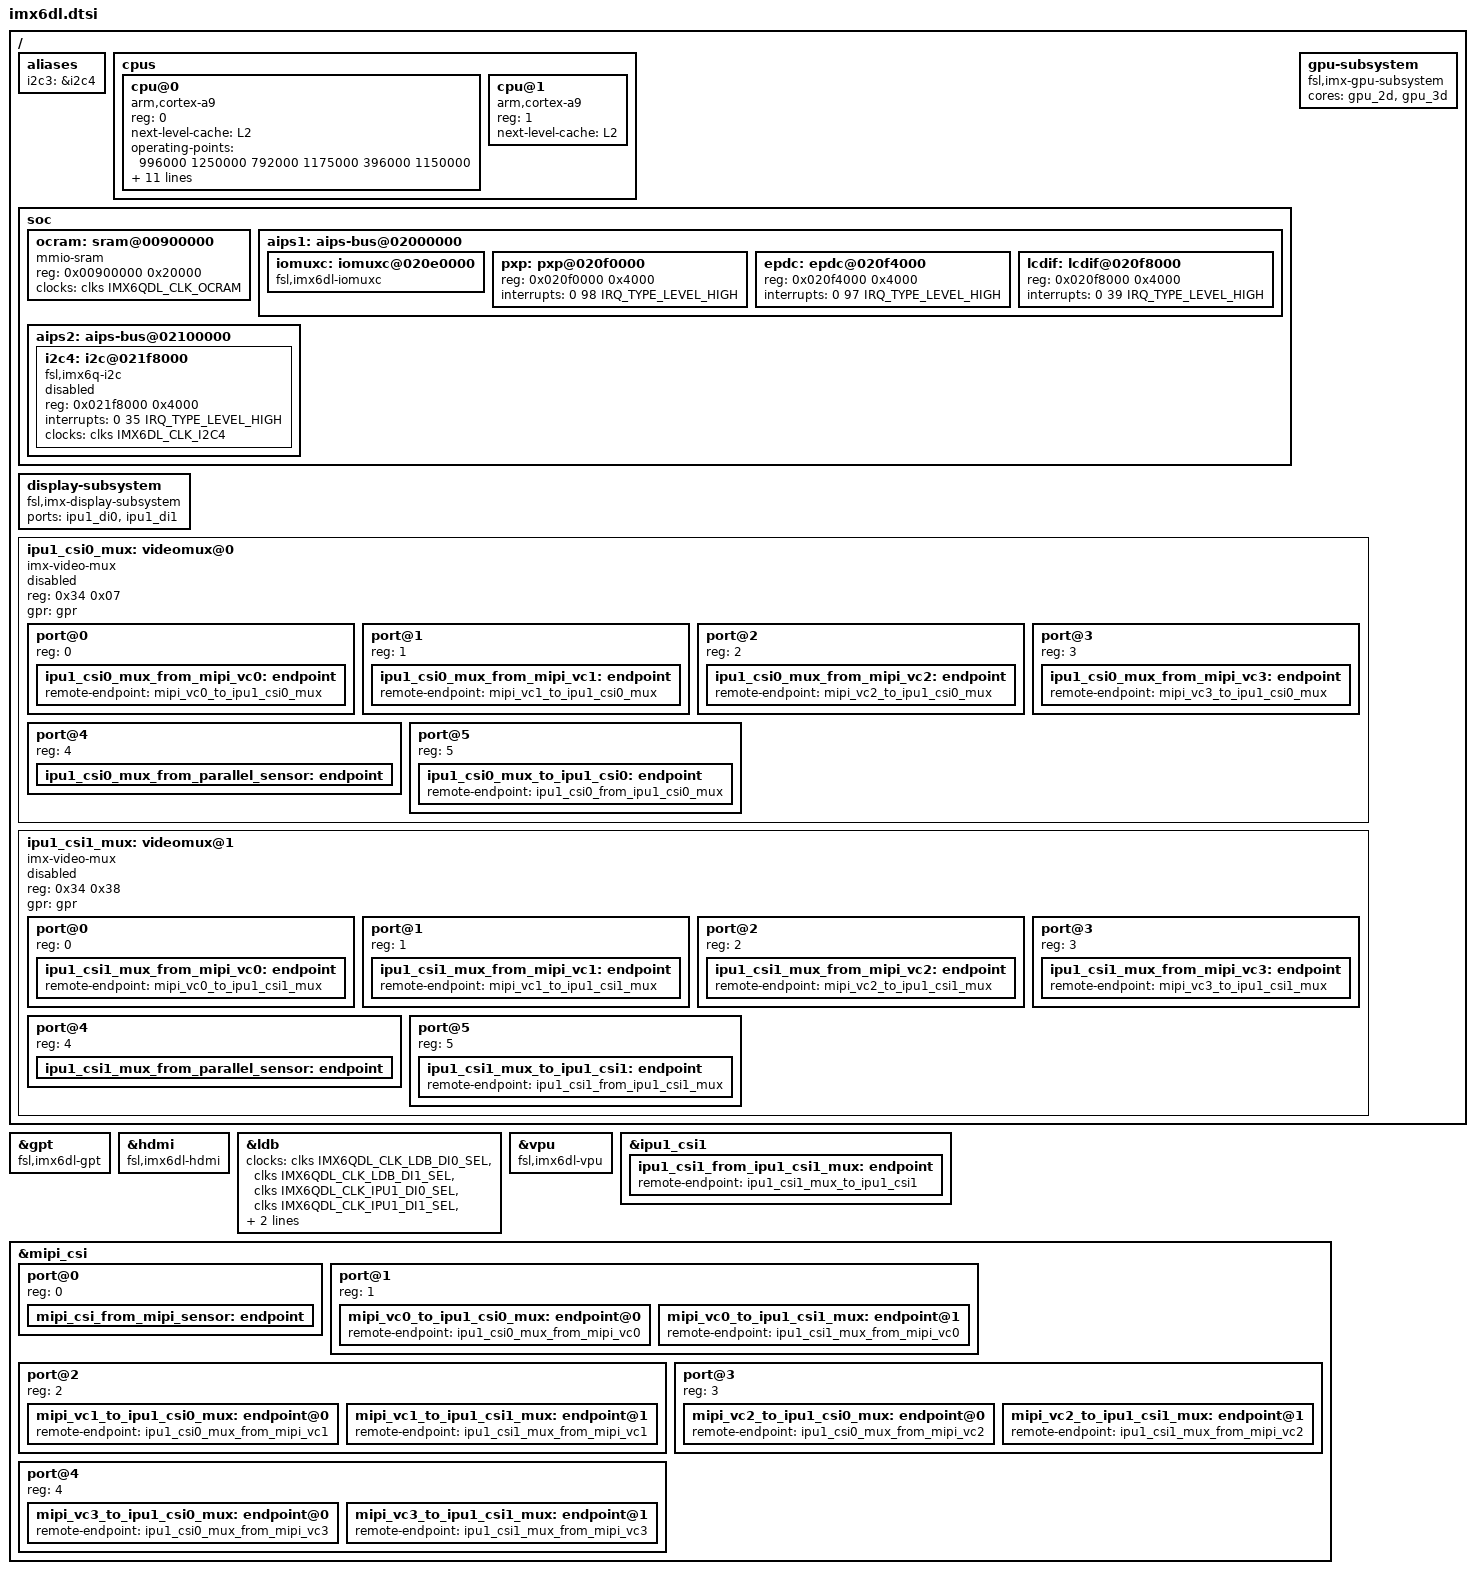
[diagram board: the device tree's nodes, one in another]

/*
 * Copyright 2013 Freescale Semiconductor, Inc.
 *
 * This program is free software; you can redistribute it and/or modify
 * it under the terms of the GNU General Public License version 2 as
 * published by the Free Software Foundation.
 *
 */

#include <dt-bindings/interrupt-controller/irq.h>
#include "imx6dl-pinfunc.h"
#include "imx6qdl.dtsi"

/ {
	aliases {
		i2c3 = &i2c4;
	};

	cpus {
		#address-cells = <1>;
		#size-cells = <0>;

		cpu@0 {
			compatible = "arm,cortex-a9";
			device_type = "cpu";
			reg = <0>;
			next-level-cache = <&L2>;
			operating-points = <
				/* kHz    uV */
				996000  1250000
				792000  1175000
				396000  1150000
			>;
			fsl,soc-operating-points = <
				/* ARM kHz  SOC-PU uV */
				996000	1175000
				792000	1175000
				396000	1175000
			>;
			clock-latency = <61036>; /* two CLK32 periods */
			clocks = <&clks IMX6QDL_CLK_ARM>,
				 <&clks IMX6QDL_CLK_PLL2_PFD2_396M>,
				 <&clks IMX6QDL_CLK_STEP>,
				 <&clks IMX6QDL_CLK_PLL1_SW>,
				 <&clks IMX6QDL_CLK_PLL1_SYS>;
			clock-names = "arm", "pll2_pfd2_396m", "step",
				      "pll1_sw", "pll1_sys";
			arm-supply = <&reg_arm>;
			pu-supply = <&reg_pu>;
			soc-supply = <&reg_soc>;
		};

		cpu@1 {
			compatible = "arm,cortex-a9";
			device_type = "cpu";
			reg = <1>;
			next-level-cache = <&L2>;
		};
	};

	soc {
		ocram: sram@00900000 {
			compatible = "mmio-sram";
			reg = <0x00900000 0x20000>;
			clocks = <&clks IMX6QDL_CLK_OCRAM>;
		};

		aips1: aips-bus@02000000 {
			iomuxc: iomuxc@020e0000 {
				compatible = "fsl,imx6dl-iomuxc";
			};

			pxp: pxp@020f0000 {
				reg = <0x020f0000 0x4000>;
				interrupts = <0 98 IRQ_TYPE_LEVEL_HIGH>;
			};

			epdc: epdc@020f4000 {
				reg = <0x020f4000 0x4000>;
				interrupts = <0 97 IRQ_TYPE_LEVEL_HIGH>;
			};

			lcdif: lcdif@020f8000 {
				reg = <0x020f8000 0x4000>;
				interrupts = <0 39 IRQ_TYPE_LEVEL_HIGH>;
			};
		};

		aips2: aips-bus@02100000 {
			i2c4: i2c@021f8000 {
				#address-cells = <1>;
				#size-cells = <0>;
				compatible = "fsl,imx6q-i2c", "fsl,imx21-i2c";
				reg = <0x021f8000 0x4000>;
				interrupts = <0 35 IRQ_TYPE_LEVEL_HIGH>;
				clocks = <&clks IMX6DL_CLK_I2C4>;
				status = "disabled";
			};
		};
	};

	display-subsystem {
		compatible = "fsl,imx-display-subsystem";
		ports = <&ipu1_di0>, <&ipu1_di1>;
	};

	gpu-subsystem {
		compatible = "fsl,imx-gpu-subsystem";
		cores = <&gpu_2d>, <&gpu_3d>;
	};

	ipu1_csi0_mux: videomux@0 {
		compatible = "imx-video-mux";
		reg = <0x34 0x07>;
		gpr = <&gpr>;
		#address-cells = <1>;
		#size-cells = <0>;
		status = "disabled";

		port@0 {
			reg = <0>;

			ipu1_csi0_mux_from_mipi_vc0: endpoint {
				remote-endpoint = <&mipi_vc0_to_ipu1_csi0_mux>;
			};
		};

		port@1 {
			reg = <1>;

			ipu1_csi0_mux_from_mipi_vc1: endpoint {
				remote-endpoint = <&mipi_vc1_to_ipu1_csi0_mux>;
			};
		};

		port@2 {
			reg = <2>;

			ipu1_csi0_mux_from_mipi_vc2: endpoint {
				remote-endpoint = <&mipi_vc2_to_ipu1_csi0_mux>;
			};
		};

		port@3 {
			reg = <3>;

			ipu1_csi0_mux_from_mipi_vc3: endpoint {
				remote-endpoint = <&mipi_vc3_to_ipu1_csi0_mux>;
			};
		};

		port@4 {
			reg = <4>;

			ipu1_csi0_mux_from_parallel_sensor: endpoint {
			};
		};

		port@5 {
			reg = <5>;

			ipu1_csi0_mux_to_ipu1_csi0: endpoint {
				remote-endpoint = <&ipu1_csi0_from_ipu1_csi0_mux>;
			};
		};
	};

	ipu1_csi1_mux: videomux@1 {
		compatible = "imx-video-mux";
		reg = <0x34 0x38>;
		gpr = <&gpr>;
		#address-cells = <1>;
		#size-cells = <0>;
		status = "disabled";

		port@0 {
			reg = <0>;

			ipu1_csi1_mux_from_mipi_vc0: endpoint {
				remote-endpoint = <&mipi_vc0_to_ipu1_csi1_mux>;
			};
		};

		port@1 {
			reg = <1>;

			ipu1_csi1_mux_from_mipi_vc1: endpoint {
				remote-endpoint = <&mipi_vc1_to_ipu1_csi1_mux>;
			};
		};

		port@2 {
			reg = <2>;

			ipu1_csi1_mux_from_mipi_vc2: endpoint {
				remote-endpoint = <&mipi_vc2_to_ipu1_csi1_mux>;
			};
		};

		port@3 {
			reg = <3>;

			ipu1_csi1_mux_from_mipi_vc3: endpoint {
				remote-endpoint = <&mipi_vc3_to_ipu1_csi1_mux>;
			};
		};

		port@4 {
			reg = <4>;

			ipu1_csi1_mux_from_parallel_sensor: endpoint {
			};
		};

		port@5 {
			reg = <5>;

			ipu1_csi1_mux_to_ipu1_csi1: endpoint {
				remote-endpoint = <&ipu1_csi1_from_ipu1_csi1_mux>;
			};
		};
	};
};

&gpt {
	compatible = "fsl,imx6dl-gpt";
};

&hdmi {
	compatible = "fsl,imx6dl-hdmi";
};

&ldb {
	clocks = <&clks IMX6QDL_CLK_LDB_DI0_SEL>, <&clks IMX6QDL_CLK_LDB_DI1_SEL>,
		 <&clks IMX6QDL_CLK_IPU1_DI0_SEL>, <&clks IMX6QDL_CLK_IPU1_DI1_SEL>,
		 <&clks IMX6QDL_CLK_LDB_DI0>, <&clks IMX6QDL_CLK_LDB_DI1>;
	clock-names = "di0_pll", "di1_pll",
		      "di0_sel", "di1_sel",
		      "di0", "di1";
};

&vpu {
	compatible = "fsl,imx6dl-vpu", "cnm,coda960";
};

&ipu1_csi1 {
	ipu1_csi1_from_ipu1_csi1_mux: endpoint {
		remote-endpoint = <&ipu1_csi1_mux_to_ipu1_csi1>;
	};
};

&mipi_csi {
	port@0 {
		reg = <0>;

		mipi_csi_from_mipi_sensor: endpoint {
		};
	};

	port@1 {
		reg = <1>;
		#address-cells = <1>;
		#size-cells = <0>;

		mipi_vc0_to_ipu1_csi0_mux: endpoint@0 {
			remote-endpoint = <&ipu1_csi0_mux_from_mipi_vc0>;
		};

		mipi_vc0_to_ipu1_csi1_mux: endpoint@1 {
			remote-endpoint = <&ipu1_csi1_mux_from_mipi_vc0>;
		};
	};

	port@2 {
		reg = <2>;
		#address-cells = <1>;
		#size-cells = <0>;

		mipi_vc1_to_ipu1_csi0_mux: endpoint@0 {
			remote-endpoint = <&ipu1_csi0_mux_from_mipi_vc1>;
		};

		mipi_vc1_to_ipu1_csi1_mux: endpoint@1 {
			remote-endpoint = <&ipu1_csi1_mux_from_mipi_vc1>;
		};
	};

	port@3 {
		reg = <3>;
		#address-cells = <1>;
		#size-cells = <0>;

		mipi_vc2_to_ipu1_csi0_mux: endpoint@0 {
			remote-endpoint = <&ipu1_csi0_mux_from_mipi_vc2>;
		};

		mipi_vc2_to_ipu1_csi1_mux: endpoint@1 {
			remote-endpoint = <&ipu1_csi1_mux_from_mipi_vc2>;
		};
	};

	port@4 {
		reg = <4>;
		#address-cells = <1>;
		#size-cells = <0>;

		mipi_vc3_to_ipu1_csi0_mux: endpoint@0 {
			remote-endpoint = <&ipu1_csi0_mux_from_mipi_vc3>;
		};

		mipi_vc3_to_ipu1_csi1_mux: endpoint@1 {
			remote-endpoint = <&ipu1_csi1_mux_from_mipi_vc3>;
		};
	};
};
